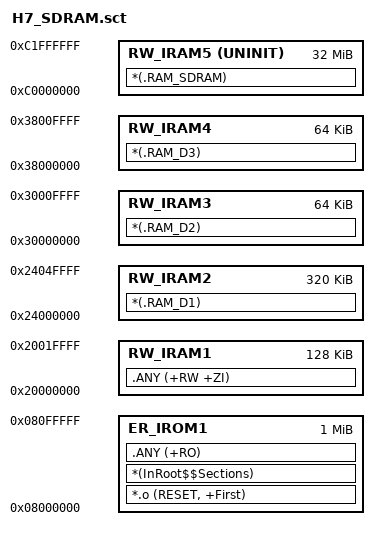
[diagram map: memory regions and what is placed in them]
; *************************************************************
; *** Scatter-Loading Description File generated by uVision ***
; *************************************************************

LR_IROM1 0x08000000 0x00100000  {    ; load region size_region
  ER_IROM1 0x08000000 0x00100000  {  ; load address = execution address
   *.o (RESET, +First)
   *(InRoot$$Sections)
   .ANY (+RO)
  }
  
  RW_IRAM1 0x20000000 0x00020000  {  ; RW data - 128KB DTCM RAM
   .ANY (+RW +ZI)
  }
  
  RW_IRAM2 0x24000000 0x00050000  {  ; RW data - 320KB AXI SRAM
   *(.RAM_D1) 
  }
  
  RW_IRAM3 0x30000000 0x00010000  {  ; RW data - D2 SRAM
   *(.RAM_D2)
  }
  
  RW_IRAM4 0x38000000 0x00010000  {  ; RW data - 64KB SRAM4
   *(.RAM_D3)
  }
  
  RW_IRAM5 0xC0000000 UNINIT 0x02000000  {  ; RW data - 32MB SDRAM
   *(.RAM_SDRAM)
  }
}
